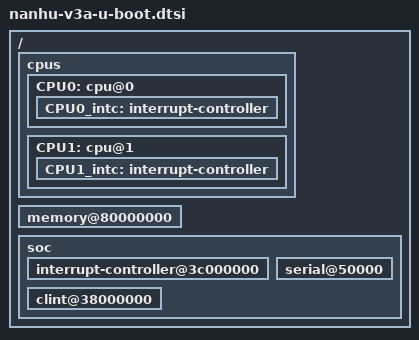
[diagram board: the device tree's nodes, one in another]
// SPDX-License-Identifier: (GPL-2.0 OR MIT)
#include "binman.dtsi"

/ {
	cpus {
		bootph-pre-ram;
		CPU0: cpu@0 {
			bootph-pre-ram;
			CPU0_intc: interrupt-controller {
				bootph-pre-ram;
			};
		};
		CPU1: cpu@1 {
			bootph-pre-ram;
			CPU1_intc: interrupt-controller {
				bootph-pre-ram;
			};
		};
	};

	memory@80000000 {
		bootph-pre-ram;
	};

	soc {
		bootph-pre-ram;

		interrupt-controller@3c000000 {
			bootph-pre-ram;
		};

		clint@38000000 {
			bootph-pre-ram;
		};

	    serial@50000 {
		    bootph-pre-ram;
	    };

	};

};
